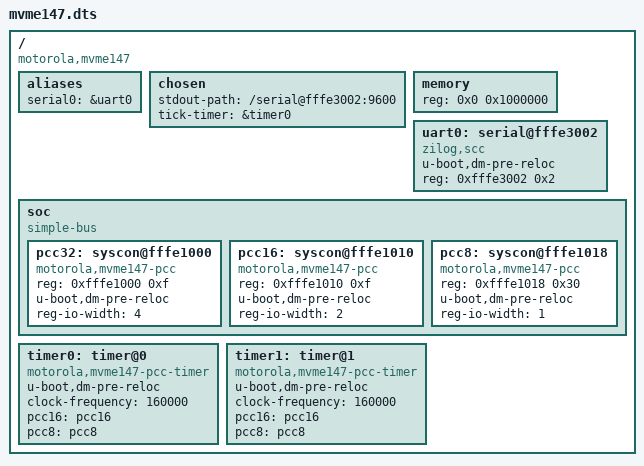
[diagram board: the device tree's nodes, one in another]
// SPDX-License-Identifier: GPL-2.0+

/dts-v1/;
#include "mc68030.dtsi"
/ {
	#address-cells = <1>;
	#size-cells = <1>;

	compatible = "motorola,mvme147";

	aliases {
		serial0 = &uart0;
	};

	chosen {
		stdout-path = "/serial@fffe3002:9600";
		tick-timer = &timer0;
	};

	memory {
		device_type = "memory";
		reg = <0x0 0x1000000>;
	};

		uart0: serial@fffe3002 {
			compatible = "zilog,scc";
			u-boot,dm-pre-reloc;
			reg = <0xfffe3002 0x2>;
			status = "okay";
		};


	soc {
		compatible = "simple-bus";
		#address-cells = <1>;
		#size-cells = <1>;

		pcc32: syscon@fffe1000 {
			compatible = "motorola,mvme147-pcc", "syscon";
			reg = <0xfffe1000 0xf>;
			u-boot,dm-pre-reloc;
			reg-io-width = <4>;
			status = "okay";
		};	

		pcc16: syscon@fffe1010 {
			compatible = "motorola,mvme147-pcc", "syscon";
			reg = <0xfffe1010 0xf>;
			u-boot,dm-pre-reloc;
			reg-io-width = <2>;
			status = "okay";
		};

		pcc8: syscon@fffe1018 {
			compatible = "motorola,mvme147-pcc", "syscon";
			reg = <0xfffe1018 0x30>;
			u-boot,dm-pre-reloc;
			reg-io-width = <1>;
			status = "okay";
		};
	};

	timer0: timer@0 {
		compatible = "motorola,mvme147-pcc-timer";
		u-boot,dm-pre-reloc;
		clock-frequency = <160000>;
		pcc16 = <&pcc16>;
		pcc8 = <&pcc8>;
		status = "okay";
	};

	timer1: timer@1 {
		compatible = "motorola,mvme147-pcc-timer";
		u-boot,dm-pre-reloc;
		clock-frequency = <160000>;
		pcc16 = <&pcc16>;
		pcc8 = <&pcc8>;
		status = "okay";
	};
};
